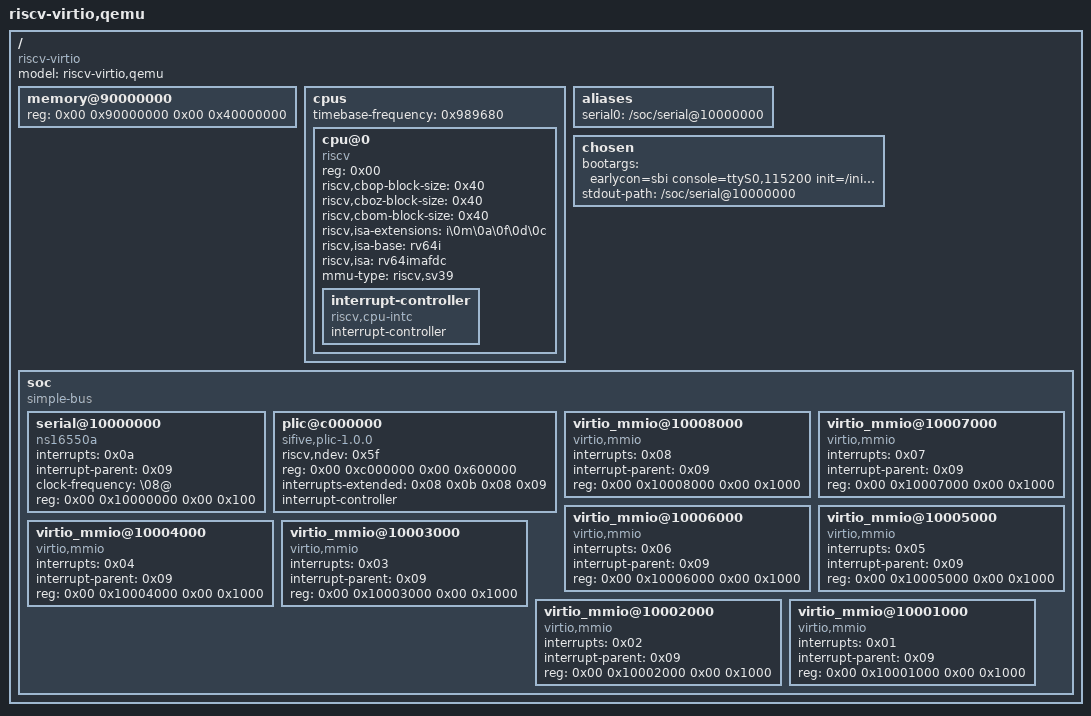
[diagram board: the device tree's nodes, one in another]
/dts-v1/;

/ {
	#address-cells = <0x02>;
	#size-cells = <0x02>;
	compatible = "riscv-virtio";
	model = "riscv-virtio,qemu";

	memory@90000000 {
		device_type = "memory";
		reg = <0x00 0x90000000 0x00 0x40000000>;
	};

	cpus {
		#address-cells = <0x01>;
		#size-cells = <0x00>;
		timebase-frequency = <0x989680>;

		cpu@0 {
			phandle = <0x07>;
			device_type = "cpu";
			reg = <0x00>;
			status = "okay";
			compatible = "riscv";
			riscv,cbop-block-size = <0x40>;
			riscv,cboz-block-size = <0x40>;
			riscv,cbom-block-size = <0x40>;
			riscv,isa-extensions = "i\0m\0a\0f\0d\0c";
			riscv,isa-base = "rv64i";
			riscv,isa = "rv64imafdc";
			mmu-type = "riscv,sv39";

			interrupt-controller {
				#interrupt-cells = <0x01>;
				interrupt-controller;
				compatible = "riscv,cpu-intc";
				phandle = <0x08>;
			};
		};
	};

	aliases {
		serial0 = "/soc/serial@10000000";
	};

	chosen {
		bootargs = "earlycon=sbi console=ttyS0,115200 init=/init root=/dev/vda rw";
		stdout-path = "/soc/serial@10000000";
	};

	soc {
		#address-cells = <0x02>;
		#size-cells = <0x02>;
		compatible = "simple-bus";
		ranges;

		serial@10000000 {
			interrupts = <0x0a>;
			interrupt-parent = <0x09>;
			clock-frequency = "\08@";
			reg = <0x00 0x10000000 0x00 0x100>;
			compatible = "ns16550a";
		};

		plic@c000000 {
			phandle = <0x09>;
			riscv,ndev = <0x5f>;
			reg = <0x00 0xc000000 0x00 0x600000>;
			interrupts-extended = <0x08 0x0b 0x08 0x09>;
			interrupt-controller;
			compatible = "sifive,plic-1.0.0\0riscv,plic0";
			#address-cells = <0x00>;
			#interrupt-cells = <0x01>;
		};
		
        virtio_mmio@10008000 {
			interrupts = <0x08>;
			interrupt-parent = <0x09>;
			reg = <0x00 0x10008000 0x00 0x1000>;
			compatible = "virtio,mmio";
		};

		virtio_mmio@10007000 {
			interrupts = <0x07>;
			interrupt-parent = <0x09>;
			reg = <0x00 0x10007000 0x00 0x1000>;
			compatible = "virtio,mmio";
		};

		virtio_mmio@10006000 {
			interrupts = <0x06>;
			interrupt-parent = <0x09>;
			reg = <0x00 0x10006000 0x00 0x1000>;
			compatible = "virtio,mmio";
		};

		virtio_mmio@10005000 {
			interrupts = <0x05>;
			interrupt-parent = <0x09>;
			reg = <0x00 0x10005000 0x00 0x1000>;
			compatible = "virtio,mmio";
		};

		virtio_mmio@10004000 {
			interrupts = <0x04>;
			interrupt-parent = <0x09>;
			reg = <0x00 0x10004000 0x00 0x1000>;
			compatible = "virtio,mmio";
		};

		virtio_mmio@10003000 {
			interrupts = <0x03>;
			interrupt-parent = <0x09>;
			reg = <0x00 0x10003000 0x00 0x1000>;
			compatible = "virtio,mmio";
		};

		virtio_mmio@10002000 {
			interrupts = <0x02>;
			interrupt-parent = <0x09>;
			reg = <0x00 0x10002000 0x00 0x1000>;
			compatible = "virtio,mmio";
		};

		virtio_mmio@10001000 {
			interrupts = <0x01>;
			interrupt-parent = <0x09>;
			reg = <0x00 0x10001000 0x00 0x1000>;
			compatible = "virtio,mmio";
		};
    };
};
